VERSION ""

NS_ :

BS_:

BU_: XXX

BO_ 520 brakeandspeed: 8 XXX
 SG_ Brake : 19|12@0+ (1,0) [0|255] "" XXX
 SG_ speed : 55|16@0+ (.0001,0) [0|65535] "kph" XXX

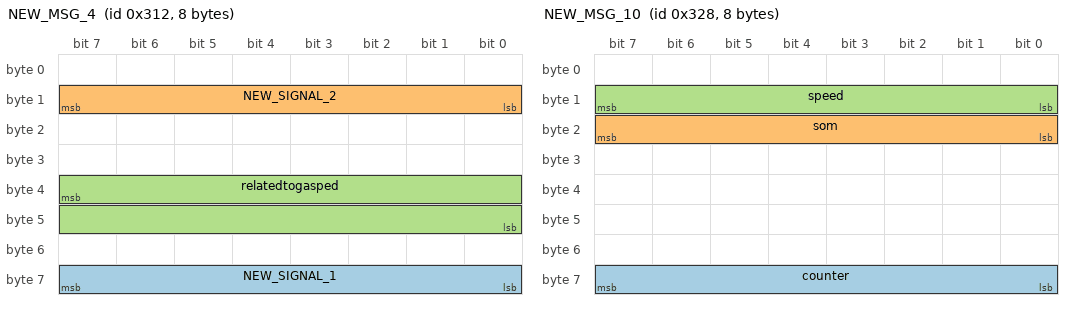
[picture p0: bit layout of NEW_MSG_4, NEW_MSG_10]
BO_ 786 NEW_MSG_4: 8 XXX
 SG_ NEW_SIGNAL_1 : 63|8@0+ (1,0) [0|255] "" XXX
 SG_ NEW_SIGNAL_2 : 8|8@1+ (1,0) [0|255] "" XXX
 SG_ relatedtogasped : 39|16@0+ (1,0) [0|65535] "" XXX

BO_ 776 NEW_MSG_3: 8 XXX
 SG_ relatedtogaspeda : 15|16@0+ (1,0) [0|65535] "" XXX

BO_ 566 hassteering: 8 XXX
 SG_ NEW_SIGNAL_1 : 31|16@0+ (1,0) [0|65535] "" XXX
 SG_ strangl : 3|12@0- (1,0) [-360|360] "" XXX

BO_ 512 NEW_MSG_1: 8 XXX

BO_ 528 NEW_MSG_2: 8 XXX

BO_ 530 NEW_MSG_5: 8 XXX
 SG_ relatedtogaspedalb : 53|14@0+ (1,0) [0|255] "" XXX

BO_ 533 NEW_MSG_6: 8 XXX
 SG_ relatedtogaspedal : 3|12@0+ (1,0) [0|4095] "" XXX

BO_ 768 steering: 8 XXX
 SG_ steering : 40|16@1+ (1,0) [0|255] "" XXX

BO_ 789 NEW_MSG_8: 8 XXX

BO_ 805 NEW_MSG_9: 8 XXX
 SG_ someh1 : 39|8@0+ (1,0) [0|255] "" XXX

BO_ 808 NEW_MSG_10: 8 XXX
 SG_ counter : 63|8@0+ (1,0) [0|255] "" XXX
 SG_ som : 16|8@1+ (1,0) [0|255] "" XXX
 SG_ speed : 8|8@1+ (1,0) [0|255] "" XXX

BO_ 848 NEW_MSG_11: 8 XXX

BO_ 752 has_gas_pedal: 8 XXX
 SG_ gas_pedal : 24|8@1+ (1,0) [0|255] "" XXX
 SG_ relatedtogaspedal : 0|8@1+ (1,0) [0|255] "" XXX

BO_ 840 NEW_MSG_7: 8 XXX

BO_ 996 NEW_MSG_12: 8 XXX
 SG_ counter : 16|8@1+ (1,0) [0|255] "" XXX

CM_ SG_ 566 strangl "Positive is left";
